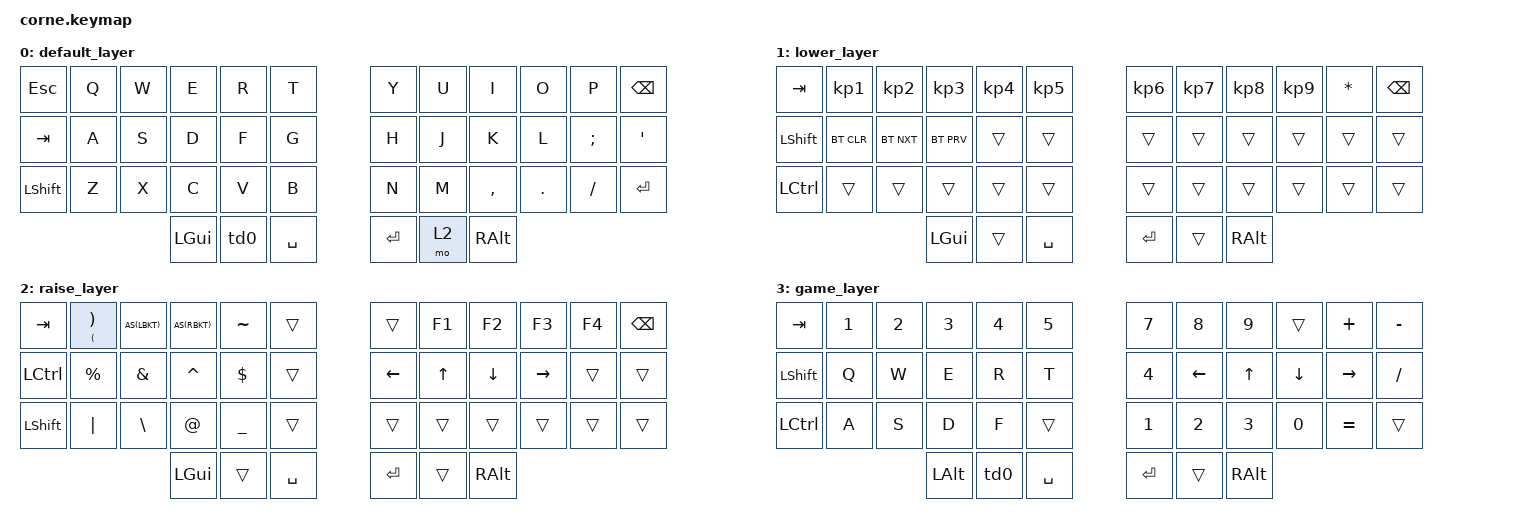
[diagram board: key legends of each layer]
/*
 * Copyright (c) 2020 The ZMK Contributors
 *
 * SPDX-License-Identifier: MIT
 */

#include <behaviors.dtsi>
#include <dt-bindings/zmk/keys.h>
#include <dt-bindings/zmk/bt.h>
#define AS(keycode) &as LS(keycode) keycode     // Autoshift Macro

/ {

        behaviors {
        as: auto_shift {
            compatible = "zmk,behavior-hold-tap";
            #binding-cells = <2>;
            tapping_term_ms = <250>;
            quick_tap_ms = <0>;
            flavor = "tap-preferred";
            bindings = <&kp>, <&kp>;
        };

        td0: tap_dance_0 {
            compatible = "zmk,behavior-tap-dance";
            #binding-cells = <0>;
            tapping-term-ms = <200>;
            bindings = <&mo 1>, <&tog 3>;
        };
    };
        keymap {
                compatible = "zmk,keymap";

                default_layer {
// -----------------------------------------------------------------------------------------
// | ESC  |  Q  |  W  |  E  |  R  |  T  |   |   Y  |  U   |  I  |  O  |  P  | BKSP/DEL |
// | TAB  |  A  |  S  |  D  |  F  |  G  |   |   H  |  J   |  K  |  L  |  ;  |  '   |
// | CTRL |  Z  |  X  |  C  |  V  |  B  |   |   N  |  M   |  ,  |  .  |  /  | SHFT  |
//                    | GUI | LWR | SPC |   | ENTR | RSE  | ALT |
                        bindings = <
   &kp ESC     &kp Q &kp W &kp E    &kp R &kp T        &kp Y   &kp U  &kp I     &kp O       &kp P      &kp BSPC
   &kp TAB     &kp A &kp S &kp D    &kp F &kp G        &kp H   &kp J  &kp K     &kp L       &kp SEMI   &kp APOS
   &kp LSHFT   &kp Z &kp X &kp C    &kp V &kp B        &kp N   &kp M  &kp COMMA &kp PERIOD  &kp SLASH  &kp ENTER
                           &kp LGUI &td0  &kp SPACE    &kp RET &mo 2  &kp RALT
                        >;
                };
                lower_layer {
// -----------------------------------------------------------------------------------------
// |  TAB |  1            |  2        |  3        |  4        |  5  |  6  |  7  |  8  |  9  |   0  |     |  BKSP   |
// | SHFT |  BT_CLR_All   |   BT_NXT  |  BT_PRV   |  BT_SEL   |     |     |     |     |     |      |     |         |
// | CTRL |               |           |           |           |     |     |     |     |     |      |     |         |
//                   | GUI |     | SPC |   | ENT |     | ALT |
                        bindings = <
   &kp TAB   &kp KP_N1       &kp KP_N2   &kp KP_N3  &kp KP_N4   &kp KP_N5   &kp KP_N6   &kp KP_N7   &kp KP_N8 &kp KP_N9   &kp STAR   &kp BSPC
   &kp LSHFT &bt BT_CLR      &bt BT_NXT  &bt BT_PRV &trans      &trans      &trans      &trans      &trans    &trans      &trans     &trans
   &kp LCTRL &trans          &trans      &trans     &trans      &trans      &trans      &trans      &trans    &trans      &trans     &trans
                             &kp LGUI    &trans     &kp SPACE   &kp RET     &trans      &kp RALT
                        >;
                };

                raise_layer {
// -----------------------------------------------------------------------------------------
// |  TAB |  ( -> )  |  [ -> {  |  ] -> }  |    ~   |     |    |     |     |    |    |     | BKSP |
// | CTRL |     %    |     &    |     ^    |    $   |     |    |     |     |    |    |     |      |
// | SHFT |    '|'   |     \    |     @    |    _   |     |    |     |     |    |    |     |      |
//                    | GUI |     | SPC |     | ENT |       | ALT  |
                        bindings = <
   &kp  TAB  &mt LPAR RPAR AS(LBKT)      AS(RBKT)      &kp TILDE     &trans      &trans    &kp F1   &kp F2   &kp F3     &kp F4     &kp BSPC
   &kp LCTRL &kp PERCENT   &kp AMPS      &kp CARET     &kp DLLR      &trans      &kp LEFT  &kp UP   &kp DOWN &kp RIGHT  &trans     &trans
   &kp LSHFT &kp PIPE      &kp BSLH      &kp AT        &kp UNDER     &trans      &trans   &trans    &trans   &trans     &trans     &trans
                           &kp LGUI      &trans        &kp SPACE     &kp RET     &trans   &kp RALT
                        >;
                };

              game_layer {
// -----------------------------------------------------------------------------------------
// |  TAB  |  1   |  2   |  3   |  4   |   5  |     |  ESC  |         |       |          |           |      |
// |  SHFT |  Q   |  W   |  E   |  R   |   T  |     |       |   LEFT  |   UP  |   DOWN   |   RIGHT   |      |
// | CTRL  |  A   |   S  |   D  |   F  |      |     |       |         |       |          |           |      |
//                   | ALT |     | SPC |  SPC |     |  ALT  |
                        bindings = <
   &kp TAB    &kp N1   &kp N2    &kp N3    &kp N4     &kp N5         &kp N7   &kp N8    &kp N9   &trans     &kp PLUS    &kp MINUS
   &kp LSHFT  &kp Q    &kp W     &kp E     &kp R      &kp T          &kp N4   &kp LEFT  &kp UP   &kp DOWN   &kp RIGHT   &kp FSLH 
   &kp LCTRL  &kp A    &kp S     &kp D     &kp F      &trans         &kp N1   &kp N2    &kp N3   &kp N0     &kp EQUAL   &trans
                                 &kp LALT  &td0       &kp SPACE      &kp RET  &trans    &kp RALT
                        >;
                };  
        };    
};
